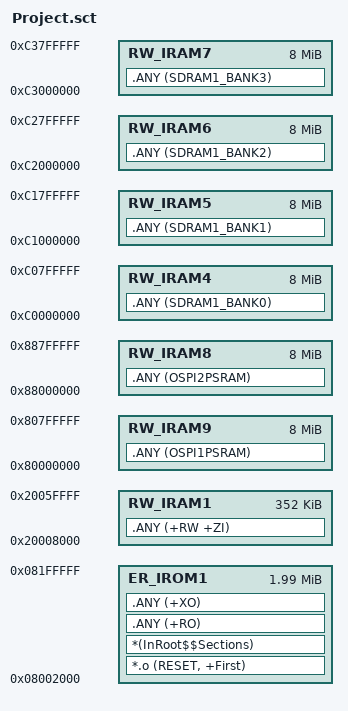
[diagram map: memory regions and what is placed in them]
; *************************************************************
; *** Scatter-Loading Description File generated by uVision ***
; *************************************************************

;LR_IROM1 0x08002000 0x00020000  {    ; load region size_region
;  ER_IROM1 0x08002000 0x00020000  {  ; load address = execution address
LR_IROM1 0x08002000 0x001FE000  {    ; load region size_region
  ER_IROM1 0x08002000 0x001FE000  {  ; load address = execution address
   *.o (RESET, +First)
   *(InRoot$$Sections)
   .ANY (+RO)
   .ANY (+XO)
  }
  RW_IRAM1 0x20008000 0x00058000  {  ; RW data
   .ANY (+RW +ZI)
  }
;  RW_IRAM2 0x20030000 0x00030000  {	;
;   RW_IRAM2 0x20030000 0x00050000  {	;
;   .ANY (IRAM2)
;  }
;  RW_IRAM3 0xC0000000 0x02000000  {
;   .ANY (SDRAM1)
;  }
  RW_IRAM4 0xC0000000 0x00800000  {
   .ANY (SDRAM1_BANK0)
  }
  RW_IRAM5 0xC1000000 0x00800000  {
   .ANY (SDRAM1_BANK1)
  }
  RW_IRAM6 0xC2000000 0x00800000  {
   .ANY (SDRAM1_BANK2)
  }
  RW_IRAM7 0xC3000000 0x00800000  {
   .ANY (SDRAM1_BANK3)
  }
  RW_IRAM8 0x88000000 0x00800000  {
   .ANY (OSPI2PSRAM)
  }
  RW_IRAM9 0x80000000 0x00800000  {
   .ANY (OSPI1PSRAM)
  }
}

